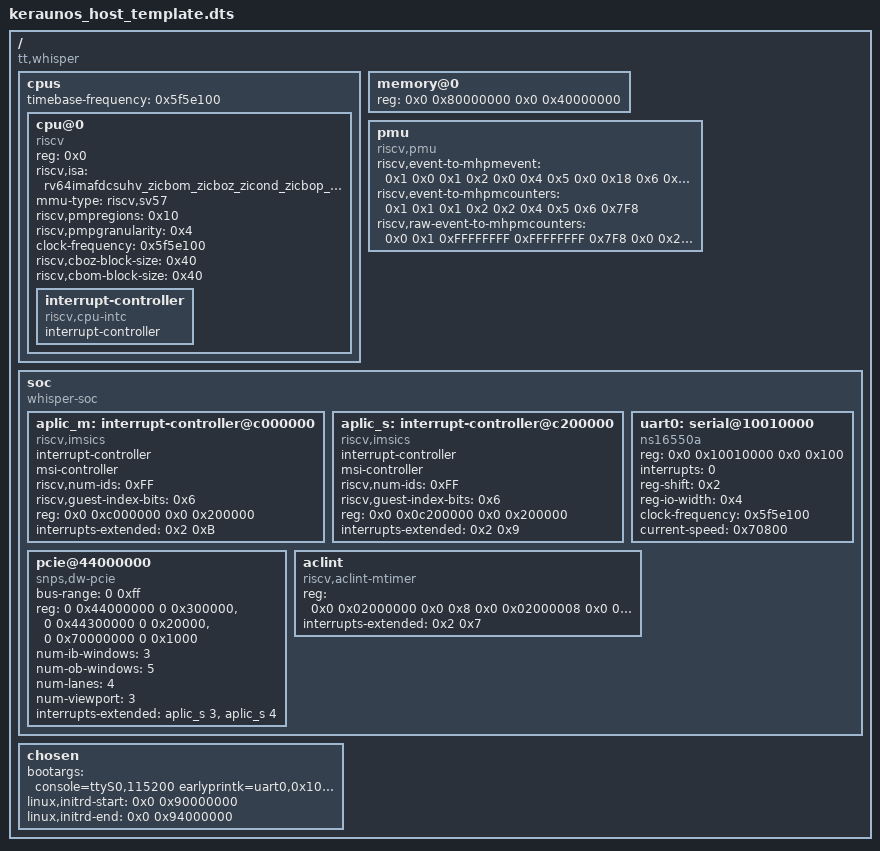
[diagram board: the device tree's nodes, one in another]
// SPDX-License-Identifier: GPL-2.0-or-later OR MIT
//
// Keraunos PCIE Tile — host mini-linux device tree TEMPLATE.
//
// Origin: Copied from Ascalon Ascalon_Chiplet_System/software/mini-riscv64-linux/DTS/ascalon_pcirc.dts
// as a starting point (Whisper-style SoC + PC RC PCIe node).
//
// BEFORE USE: Reconcile every reg/range/interrupt with the Keraunos_PCIE_Tile Virtualizer
// platform (Host_Chiplet memory map, UART, Rocket ISA extensions, PCIe RC windows).
//

/dts-v1/;
 
/ {
    #address-cells = <0x2>;
    #size-cells = <0x2>;
    compatible = "tt,whisper";
    cpus {
        #address-cells = <0x1>;
        #size-cells = <0x0>;
        //timebase-frequency = <0x3B9ACA00>;
	timebase-frequency = <0x5f5e100>;
        linux,phandle = <0xC>;
        phandle = <0xC>;
        cpu@0 {
            device_type = "cpu";
            reg = <0x0>;
            status = "okay";
            compatible = "riscv";
		riscv,isa = "rv64imafdcsuhv_zicbom_zicboz_zicond_zicbop_zfa_zfh_zcb_zba_zbs_zvbb_zvfh_zvkb_zvkg_zvkned_zvknhb_sstc_smaia_ssaia_sscofpmf_smstateen_svnapot_svpbmt_svade";
            mmu-type = "riscv,sv57";
            riscv,pmpregions = <0x10>;
            riscv,pmpgranularity = <0x4>;
            //clock-frequency = <0x3B9ACA00>;
	    clock-frequency = <0x5f5e100>;
            riscv,cboz-block-size = <0x40>;
            riscv,cbom-block-size = <0x40>;
            linux,phandle = <0xD>;
            phandle = <0xD>;
            interrupt-controller {
                #interrupt-cells = <0x1>;
                interrupt-controller;
                compatible = "riscv,cpu-intc";
                phandle = <0x2>;
            };
        };
    };
    memory@0 {
        device_type = "memory";
        reg = <0x0 0x80000000 0x0 0x40000000>;
        linux,phandle = <0xB>;
        phandle = <0xB>;
    };
    pmu {
        compatible = "riscv,pmu";
        #interrupt-cells=<0>;
        riscv,event-to-mhpmevent = <0x1 0x0 0x1 0x2 0x0 0x4 0x5 0x0 0x18 0x6 0x0 0x19>;
        riscv,event-to-mhpmcounters = <0x1 0x1 0x1 0x2 0x2 0x4 0x5 0x6 0x7F8>;
        riscv,raw-event-to-mhpmcounters = <0x0 0x1 0xFFFFFFFF 0xFFFFFFFF 0x7F8 0x0 0x2 0xFFFFFFFF 0xFFFFFFFF 0x7F8 0x0 0x3 0xFFFFFFFF 0xFFFFFFFF 0x7F8 0x0 0x4 0xFFFFFFFF 0xFFFFFFFF 0x7F8 0x0 0x5 0xFFFFFFFF 0xFFFFFFFF 0x7F8 0x0 0x6 0xFFFFFFFF 0xFFFFFFFF 0x7F8 0x0 0x7 0xFFFFFFFF 0xFFFFFFFF 0x7F8 0x0 0x8 0xFFFFFFFF 0xFFFFFFFF 0x7F8 0x0 0x9 0xFFFFFFFF 0xFFFFFFFF 0x7F8 0x0 0xA 0xFFFFFFFF 0xFFFFFFFF 0x7F8 0x0 0xB 0xFFFFFFFF 0xFFFFFFFF 0x7F8 0x0 0xC 0xFFFFFFFF 0xFFFFFFFF 0x7F8 0x0 0xD 0xFFFFFFFF 0xFFFFFFFF 0x7F8 0x0 0xE 0xFFFFFFFF 0xFFFFFFFF 0x7F8 0x0 0xF 0xFFFFFFFF 0xFFFFFFFF 0x7F8 0x0 0x10 0xFFFFFFFF 0xFFFFFFFF 0x7F8 0x0 0x11 0xFFFFFFFF 0xFFFFFFFF 0x7F8 0x0 0x12 0xFFFFFFFF 0xFFFFFFFF 0x7F8 0x0 0x13 0xFFFFFFFF 0xFFFFFFFF 0x7F8 0x0 0x14 0xFFFFFFFF 0xFFFFFFFF 0x7F8 0x0 0x15 0xFFFFFFFF 0xFFFFFFFF 0x7F8 0x0 0x16 0xFFFFFFFF 0xFFFFFFFF 0x7F8 0x0 0x17 0xFFFFFFFF 0xFFFFFFFF 0x7F8 0x0 0x18 0xFFFFFFFF 0xFFFFFFFF 0x7F8 0x0 0x19 0xFFFFFFFF 0xFFFFFFFF 0x7F8 0x0 0x1A 0xFFFFFFFF 0xFFFFFFFF 0x7F8 0x0 0x1B 0xFFFFFFFF 0xFFFFFFFF 0x7F8 0x0 0x1C 0xFFFFFFFF 0xFFFFFFFF 0x7F8 0x0 0x1D 0xFFFFFFFF 0xFFFFFFFF 0x7F8 0x0 0x1E 0xFFFFFFFF 0xFFFFFFFF 0x7F8 0x0 0x1F 0xFFFFFFFF 0xFFFFFFFF 0x7F8 0x0 0x20 0xFFFFFFFF 0xFFFFFFFF 0x7F8 0x0 0x21 0xFFFFFFFF 0xFFFFFFFF 0x7F8 0x0 0x22 0xFFFFFFFF 0xFFFFFFFF 0x7F8 0x0 0x23 0xFFFFFFFF 0xFFFFFFFF 0x7F8 0x0 0x24 0xFFFFFFFF 0xFFFFFFFF 0x7F8 0x0 0x25 0xFFFFFFFF 0xFFFFFFFF 0x7F8 0x0 0x26 0xFFFFFFFF 0xFFFFFFFF 0x7F8 0x0 0x27 0xFFFFFFFF 0xFFFFFFFF 0x7F8 0x0 0x28 0xFFFFFFFF 0xFFFFFFFF 0x7F8 0x0 0x29 0xFFFFFFFF 0xFFFFFFFF 0x7F8 0x0 0x2A 0xFFFFFFFF 0xFFFFFFFF 0x7F8 0x0 0x2B 0xFFFFFFFF 0xFFFFFFFF 0x7F8 0x0 0x2C 0xFFFFFFFF 0xFFFFFFFF 0x7F8 0x0 0x2D 0xFFFFFFFF 0xFFFFFFFF 0x7F8 0x0 0x2E 0xFFFFFFFF 0xFFFFFFFF 0x7F8 0x0 0x2F 0xFFFFFFFF 0xFFFFFFFF 0x7F8 0x0 0x30 0xFFFFFFFF 0xFFFFFFFF 0x7F8 0x0 0x31 0xFFFFFFFF 0xFFFFFFFF 0x7F8 0x0 0x32 0xFFFFFFFF 0xFFFFFFFF 0x7F8 0x0 0x33 0xFFFFFFFF 0xFFFFFFFF 0x7F8 0x0 0x34 0xFFFFFFFF 0xFFFFFFFF 0x7F8 0x0 0x35 0xFFFFFFFF 0xFFFFFFFF 0x7F8 0x0 0x36 0xFFFFFFFF 0xFFFFFFFF 0x7F8 0x0 0x37 0xFFFFFFFF 0xFFFFFFFF 0x7F8 0x0 0x38 0xFFFFFFFF 0xFFFFFFFF 0x7F8 0x0 0x39 0xFFFFFFFF 0xFFFFFFFF 0x7F8 0x0 0x3A 0xFFFFFFFF 0xFFFFFFFF 0x7F8 0x0 0x3B 0xFFFFFFFF 0xFFFFFFFF 0x7F8 0x0 0x3C 0xFFFFFFFF 0xFFFFFFFF 0x7F8 0x0 0x3D 0xFFFFFFFF 0xFFFFFFFF 0x7F8 0x0 0x3E 0xFFFFFFFF 0xFFFFFFFF 0x7F8 0x0 0x3F 0xFFFFFFFF 0xFFFFFFFF 0x7F8>;
        linux,phandle = <0xA>;
        phandle = <0xA>;
    };
    
    
    soc {
        #address-cells = <0x2>;
        #size-cells = <0x2>;
        #interrupt-cells = <0x0>;
        compatible = "whisper-soc", "simple-bus";
        ranges;
        linux,phandle = <0x5>;
        phandle = <0x5>;
        aplic_m: interrupt-controller@c000000 {
            compatible = "riscv,imsics";
            interrupt-controller;
            #interrupt-cells = <0x1>;
            msi-controller;
            #msi-cells = <0x0>;
            riscv,num-ids = <0xFF>;
            riscv,guest-index-bits = <0x6>;
            reg = <0x0 0xc000000 0x0 0x200000>;
            phandle = <0x1>;
            interrupts-extended = <0x2 0xB>;
        };
        aplic_s: interrupt-controller@c200000 {
            compatible = "riscv,imsics";
            interrupt-controller;
            #interrupt-cells = <0x1>;
            msi-controller;
            #msi-cells = <0x0>;
            riscv,num-ids = <0xFF>;
            riscv,guest-index-bits = <0x6>;
            reg = <0x0 0x0c200000 0x0 0x200000>;
            interrupts-extended = <0x2 0x9>;
            linux,phandle = <0x8>;
            phandle = <0x8>;
        };
        
        uart0: serial@10010000 {
        compatible = "ns16550a";
        reg = <0x0 0x10010000 0x0 0x100>;
	//interrupts-extended = <&aplic_m 0x0>;
	interrupts = <0>;
	//#interrupt-cells=<1>;
	//interrupt-parent=<&aplic_m>;
        reg-shift = <0x2>;
        reg-io-width = <0x4>;
        //clock-frequency = <0x2FAF080>;
	clock-frequency = <0x5f5e100>;
        current-speed = <0x70800>;
        linux,phandle = <0x9>;
        phandle = <0x9>;
    };
    
    pcie@44000000 {
	 compatible = "snps,dw-pcie";
	 bus-range = <0 0xff>;
	 reg-names = "dbi", "atu", "config";
	 reg = 	<0 0x44000000 0 0x300000>,   /* IP registers - DBI */
			<0 0x44300000 0 0x20000>, /* atu */
			<0 0x70000000 0 0x1000>;  /* Config space */
	 num-ib-windows = <3>;
	 num-ob-windows = <5>;
	 num-lanes = <4>;
	 num-viewport = <3>;
	 #address-cells = <3>;
	 #size-cells = <2>;
	 device_type = "pci";
	 ranges = <0x02000000 0x0 0x10000000 0 0x71000000 0x0 0xF000000>;
	 interrupts-extended = <&aplic_s 3>, <&aplic_s 4>;
};

        aclint {
            compatible = "riscv,aclint-mtimer";
	    reg = <0x0 0x02000000 0x0 0x8 0x0 0x02000008 0x0 0x40 0x0 0x02000048 0x0 0x20 0x0 0x02000068 0x0 0x20>;
            interrupts-extended = <0x2 0x7>;
            linux,phandle = <0x7>;
            phandle = <0x7>;
        };
       
    };
    chosen {
	bootargs = "console=ttyS0,115200 earlyprintk=uart0,0x10010000 printk.time=1 		printk.devkmsg=on acpi=off loglevel=9 earlycon=sbi initcall_debug=0 nokaslr";
        linux,initrd-start = <0x0 0x90000000>;
        linux,initrd-end = <0x0 0x94000000>;
        linux,phandle = <0x4>;
        phandle = <0x4>;
    };
};
